# RS14100 register map
File version: 1.0
CPU: CM4 r0p1, little endian, MPU, FPU, 4 interrupt priority bits
Registers are 32-bit, read-write, reset 0x0 unless marked. A register's access mark holds for its fields unless they carry their own. Offsets are from the block's base; [hi:lo] are bit positions; {n}, {i} and the like mark numbered series; 'fields as' and 'values as' point back to an identical list.

## MCUULP_CLOCK — The MCU ULP (Ultra Low Power) domain contains the MCU ULP AHB Inter-Connect-Matrix, MCU ULP Peripherals and the direct AHB Interface with the Processor. This section describes the different clock sources possible for each peripheral and the AHB/APB Interfaces.
Base 0x24041400
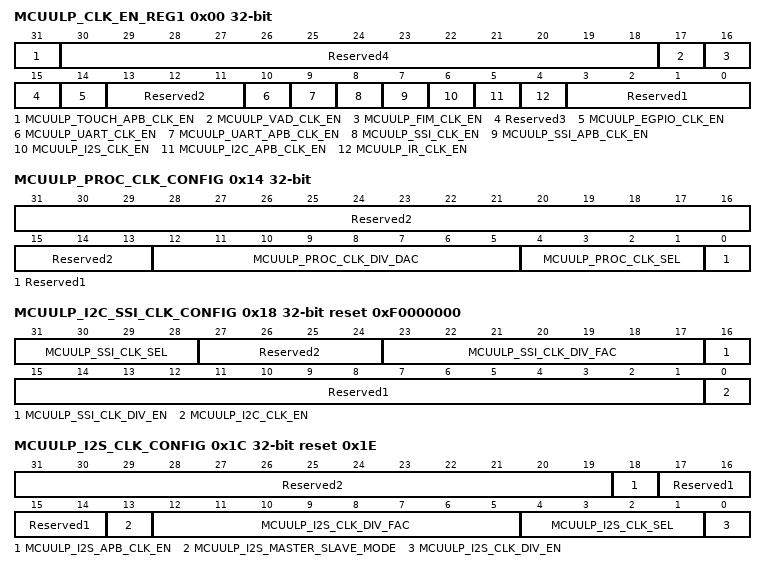
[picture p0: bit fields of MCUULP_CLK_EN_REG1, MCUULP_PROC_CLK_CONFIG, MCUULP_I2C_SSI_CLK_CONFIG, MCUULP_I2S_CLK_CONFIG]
0x00 MCUULP_CLK_EN_REG1 — MCU-ULP Clock Enable Register 1
  [31] MCUULP_TOUCH_APB_CLK_EN — ULP VAD clock enable
    0=Disable (Writing 0 to this disables clock to Touch Sensor APB Interface.); 1=Enable (Writing 1 to this enables clock to Touch Sensor APB Interface.)
  [30:18] Reserved4 — It is recommended to retain the contents by using read/modify write to this register.
  [17] MCUULP_VAD_CLK_EN — ULP VAD clock enable
    0=Disable (Writing 0 to this disables clock to VAD Controller.); 1=Enable (Writing 1 to this enables clock to VAD Controller.)
  [16] MCUULP_FIM_CLK_EN — ULP FIM clock enable
    0=Disable (Writing 0 to this disables clock to FIM Engine.); 1=Enable (Writing 1 to this enables clock to FIM Engine.)
  [15] Reserved3 — It is recommended to write these bits to 0.
  [14] MCUULP_EGPIO_CLK_EN — ULP EGPIO clock enable
    0=Disable (Writing 0 to this disables clock to Enhanced-GPIO.); 1=Enable (Writing 1 to this enables clock to Enhanced-GPIO.)
  [13:11] Reserved2 — It is recommended to write these bits to 0.
  [10] MCUULP_UART_CLK_EN — ULP UART clock enable
    0=Disable (Writing 0 to this disables clock to UART Controller.); 1=Enable (Writing 1 to this enables clock to UART Controller.)
  [9] MCUULP_UART_APB_CLK_EN — ULP UART APB clock enable
    0=Disable (Writing 0 to this disables clock to UART APB Interface.); 1=Enable (Writing 1 to this enables clock to UART APB Interface.)
  [8] MCUULP_SSI_CLK_EN — ULP SSI clock enable
    0=Disable (Writing 0 to this disables clock to SPI/SSI Master.); 1=Enable (Writing 1 to this enables clock to SPI/SSI Master.)
  [7] MCUULP_SSI_APB_CLK_EN — ULP SSI APB clock enable
    0=Disable (Writing 0 to this disables clock to SPI/SSI Master APB Interface.); 1=Enable (Writing 1 to this enables clock to SPI/SSI Master APB Interface.)
  [6] MCUULP_I2S_CLK_EN — ULP I2S clock enable
    0=Disable (Writing 0 to this disables clock to I2S Controller.); 1=Enable (Writing 1 to this enables clock to I2S Controller.)
  [5] MCUULP_I2C_APB_CLK_EN — ULP I2C APB clock enable
    0=Disable (Writing 0 to this disables clock to I2C APB Interface.); 1=Enable (Writing 1 to this enables clock to I2C APB Interface.)
  [4] MCUULP_IR_CLK_EN — ULP IR receiver clock enable
    0=Disable (Writing 0 to this disables clock to IR Receiver.); 1=Enable (Writing 1 to this enables clock to IR Receiver.)
  [3:0] Reserved1 — It is recommended to retain the contents by using read/modify write to this register.
0x14 MCUULP_PROC_CLK_CONFIG — MCU-ULP AHB Clock Configuration Register
  [31:13] Reserved2 — It is recommended to write these bits to 0.
  [12:5] MCUULP_PROC_CLK_DIV_DAC — Specifies the clock division factor for AHB Interface Clock.
  [4:1] MCUULP_PROC_CLK_SEL — ULP Processor clock select
    0=MCU-ULP Reference Clock; 1=ro_32khz_clk; 2=rc_32khz_clk; 3=xtal_32khz_clk; 4=rc_32mhz_clk; 5=ro_hf_clk; 6=MCU-HP ULP Clock; 7=doubler_clk; {v}=Output clock is gated (v=8..15)
  [0] Reserved1 — It is recommended to retain the contents by using read/modify write to this register.
0x18 MCUULP_I2C_SSI_CLK_CONFIG reset 0xF0000000 — MCU-ULP SSI Master and I2C Clock Configuration Register
  [31:28] MCUULP_SSI_CLK_SEL — ULP SSI clock select
    0=MCU-ULP Reference Clock; 1=ro_32khz_clk; 2=rc_32khz_clk; 3=xtal_32khz_clk; 4=rc_32mhz_clk; 5=ro_hf_clk; 6=MCU-HP ULP Clock; {v}=Reserved{v-6} (v=7..14); 15=Output clock is gated
  [27:24] Reserved2 — It is recommended to write these bits to 0.
  [23:17] MCUULP_SSI_CLK_DIV_FAC — Specifies the clock division factor for SPI/SSI Master Clock.
  [16] MCUULP_SSI_CLK_DIV_EN — ULP SSI clock division enables
    0=Disable (Writing 0 to this disables clock to SPI/SSI Master Clock Dividers.); 1=Enable (Writing 1 to this enables clock to SPI/SSI Master Clock Dividers.)
  [15:1] Reserved1 — It is recommended to write these bits to 0.
  [0] MCUULP_I2C_CLK_EN — ULP I2C clock enables
    0=Disable (Writing 0 to this disables clock to I2C Controller.); 1=Enable (Writing 1 to this enables clock to I2C Controller.)
0x1C MCUULP_I2S_CLK_CONFIG reset 0x1E — MCU-ULP I2S Clock Configuration Register
  [31:19] Reserved2 — It is recommended to write these bits to 0.
  [18] MCUULP_I2S_APB_CLK_EN — I2S APB clock enable
    0=Disable (Writing 0 to this disables clock to I2S APB Interface.); 1=Enable (Writing 1 to this enables clock to I2S APB Interface.)
  [17:14] Reserved1 — It is recommended to retain the contents by using read/modify write to this register.
  [13] MCUULP_I2S_MASTER_SLAVE_MODE — Enable I2S master or slave mode
    0=Slave (Writing 0 to this configures I2S to Slave Mode.); 1=Master (Writing 1 to this configures I2S to Master Mode.)
  [12:5] MCUULP_I2S_CLK_DIV_FAC — Specifies the clock division factor for I2S Master Clock.
  [4:1] MCUULP_I2S_CLK_SEL — Specifies the clock source to be used for I2S Master
    0=MCU-ULP Reference Clock; 1=ro_32khz_clk; 2=rc_32khz_clk; 3=xtal_32khz_clk; 4=rc_32mhz_clk; 5=ro_hf_clk; 6=MCU-HP ULP Clock; 7=doubler_clk; 8=i2s_pll_clk; {v}=Reserved{v-8} (v=9..14); 15=Output clock is gated
  [0] MCUULP_I2S_CLK_DIV_EN — ULP I2S clock division enable
    0=Disable (Writing 0 to this disables clock to I2S Clock Dividers.); 1=Enable (Writing 1 to this enables clock to I2S Clock Dividers.)
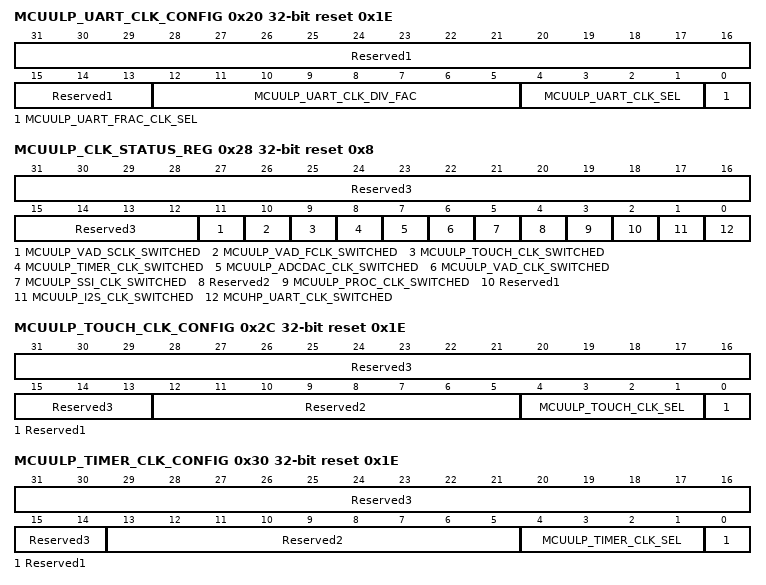
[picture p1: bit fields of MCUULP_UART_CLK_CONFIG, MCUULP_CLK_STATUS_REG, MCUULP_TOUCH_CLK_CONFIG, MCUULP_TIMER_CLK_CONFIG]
0x20 MCUULP_UART_CLK_CONFIG reset 0x1E — MCU-ULP UART Clock Configuration Register
  [31:13] Reserved1 — It is recommended to write these bits to 0.
  [12:5] MCUULP_UART_CLK_DIV_FAC — Specifies the clock division factor for UART.
  [4:1] MCUULP_UART_CLK_SEL — Specifies the clock source to be used for UART.
    0=MCU-ULP Reference Clock; 1=ro_32khz_clk; 2=rc_32khz_clk; 3=xtal_32khz_clk; 4=rc_32mhz_clk; 5=ro_hf_clk; 6=MCU-HP ULP Clock; 7=doubler_clk; {v}=Reserved{v-7} (v=8..14); 15=Output clock is gated
  [0] MCUULP_UART_FRAC_CLK_SEL — Selects the Divider type for UART Controller.
    0=Clock Swallow output is selected; 1=Fractional Clock Divider output is selected
0x28 MCUULP_CLK_STATUS_REG ro reset 0x8 — MCU-ULP Clock Status Register
  [31:12] Reserved3 — It is recommended to write these bits to 0.
  [11] MCUULP_VAD_SCLK_SWITCHED — Status of Dynamic Clock Mux in VAD Slow Clock Generation
    0=Clock switching is in progress; 1=Clock got switched and output clock can be used
  [10] MCUULP_VAD_FCLK_SWITCHED — Status of Dynamic Clock Mux in VAD Fast Clock Generation.
    values as MCUULP_VAD_SCLK_SWITCHED
  [9] MCUULP_TOUCH_CLK_SWITCHED — Status of Dynamic Clock Mux in Touch Sensor Clock Generation.
    values as MCUULP_VAD_SCLK_SWITCHED
  [8] MCUULP_TIMER_CLK_SWITCHED — Status of Dynamic Clock Mux in Timer Clock Generation.
    values as MCUULP_VAD_SCLK_SWITCHED
  [7] MCUULP_ADCDAC_CLK_SWITCHED — Status of Dynamic Clock Mux in Aux-ADC/DAC Clock Generation
    values as MCUULP_VAD_SCLK_SWITCHED
  [6] MCUULP_VAD_CLK_SWITCHED — Status of Dynamic Clock Mux in VAD Clock Generation.
    values as MCUULP_VAD_SCLK_SWITCHED
  [5] MCUULP_SSI_CLK_SWITCHED — Status of Dynamic Clock Mux in SPI/SSI Master Clock Generation.
    values as MCUULP_VAD_SCLK_SWITCHED
  [4] Reserved2 — It is recommended to write these bits to 0.
  [3] MCUULP_PROC_CLK_SWITCHED — Status of Dynamic Clock Mux in AHB Interface Clock Generation.
    values as MCUULP_VAD_SCLK_SWITCHED
  [2] Reserved1 — It is recommended to write these bits to 0.
  [1] MCUULP_I2S_CLK_SWITCHED — Status of Dynamic Clock Mux in I2S Controller Clock Generation.
    values as MCUULP_VAD_SCLK_SWITCHED
  [0] MCUHP_UART_CLK_SWITCHED — Status of Dynamic Clock Mux in UART Clock Generation.
    values as MCUULP_VAD_SCLK_SWITCHED
0x2C MCUULP_TOUCH_CLK_CONFIG reset 0x1E — MCU-ULP Touch Sensor Clock Configuration Register
  [31:13] Reserved3 — It is recommended to write these bits to 0.
  [12:5] Reserved2 — It is recommended to write these bits to 0.
  [4:1] MCUULP_TOUCH_CLK_SEL — Specifies the clock source to be used for Touch Sensor.
    values as MCUULP_I2C_SSI_CLK_CONFIG.MCUULP_SSI_CLK_SEL
  [0] Reserved1 — It is recommended to write these bits to 0.
0x30 MCUULP_TIMER_CLK_CONFIG reset 0x1E — MCU-ULP Timer Clock Configuration Register
  [31:14] Reserved3 — It is recommended to write these bits to 0.
  [13:5] Reserved2 — It is recommended to write these bits to 0.
  [4:1] MCUULP_TIMER_CLK_SEL — Specifies the clock source to be used for Timer.
    values as MCUULP_I2C_SSI_CLK_CONFIG.MCUULP_SSI_CLK_SEL
  [0] Reserved1 — It is recommended to write these bits to 0.
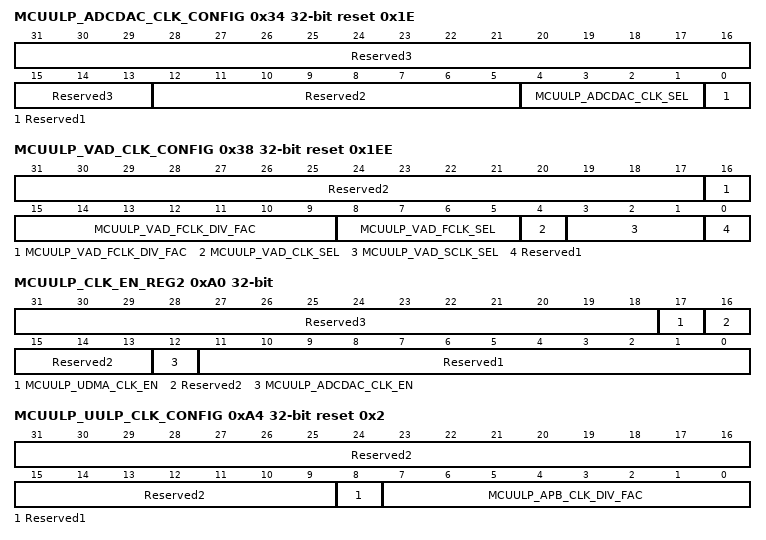
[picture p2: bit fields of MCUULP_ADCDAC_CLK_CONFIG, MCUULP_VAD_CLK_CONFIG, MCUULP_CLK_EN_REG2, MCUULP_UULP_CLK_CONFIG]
0x34 MCUULP_ADCDAC_CLK_CONFIG reset 0x1E — MCU-ULP Aux-ADC/DAC Configuration Register
  [31:13] Reserved3 — It is recommended to write these bits to 0.
  [12:5] Reserved2 — It is recommended to write these bits to 0.
  [4:1] MCUULP_ADCDAC_CLK_SEL — Specifies the clock source to be used for Aux-ADC/DAC Controller
    values as MCUULP_I2S_CLK_CONFIG.MCUULP_I2S_CLK_SEL
  [0] Reserved1 — It is recommended to write these bits to 0.
0x38 MCUULP_VAD_CLK_CONFIG reset 0x1EE — MCU-ULP VAD Configuration Register
  [31:17] Reserved2 — It is recommended to write these bits to 0.
  [16:9] MCUULP_VAD_FCLK_DIV_FAC — Specifies the clock division factor for VAD Fast clock.
  [8:5] MCUULP_VAD_FCLK_SEL — Specifies the clock source to be used for VAD Fast Clock
    0=MCU ULP AHB Interface clock; 1=MCU-ULP Reference clock; 2=rc_32mhz_clk; 3=ro_hf_clk; 4=MCU-HP ULP clock; {v}=Reserved{v-4} (v=5..14); 15=Output clock is gated
  [4] MCUULP_VAD_CLK_SEL — Specifies the clock source to be used for VAD Controller
    0=VAD Slow Clock; 1=VAD Fast Clock
  [3:1] MCUULP_VAD_SCLK_SEL — Specifies the clock source to be used for VAD Slow Clock
    0=ro_32khz_clk; 1=rc_32khz_clk; 2=xtal_32khz_clk; {v}=Reserved{v-2} (v=3..6); 7=Output clock is gated
  [0] Reserved1 — It is recommended to write these bits to 0.
0xA0 MCUULP_CLK_EN_REG2 — MCU-ULP Clock Enable Register 2
  [31:18] Reserved3 — It is recommended to write these bits to 0.
  [17] MCUULP_UDMA_CLK_EN — ULP UDMA clock enable
    0=Writing 0 to this disables clock to Aux-ADC/DAC Controller; 1=Writing 1 to this enables clock to Aux-ADC/DAC Controller
  [16:13] Reserved2 — It is recommended to write these bits to 0.
  [12] MCUULP_ADCDAC_CLK_EN — ULP ADC and DAC clock enable
    values as MCUULP_UDMA_CLK_EN
  [11:0] Reserved1 — It is recommended to write these bits to 0.
0xA4 MCUULP_UULP_CLK_CONFIG reset 0x2 — UULP APB Clock Configuration Register
  [31:9] Reserved2 — It is recommended to write these bits to 0.
  [8] Reserved1 — It is recommended to write these bits to 1.
  [7:0] MCUULP_APB_CLK_DIV_FAC — Specifies the clock division factor for UULP APB Interface.
